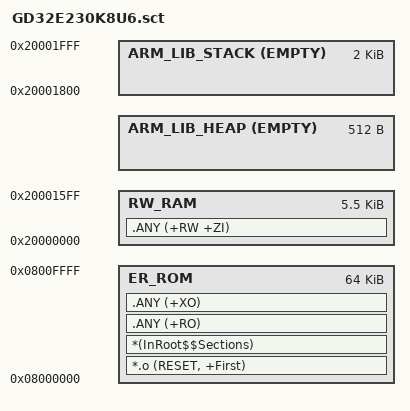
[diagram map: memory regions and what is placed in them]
#! armclang -E --target=arm-arm-none-eabi -mcpu=cortex-m23 -xc
; command above MUST be in first line

/*
;-------- <<< Use Configuration Wizard in Context Menu >>> -------------------
*/

/*--------------------- Flash Configuration ----------------------------------
; <h> Flash Configuration
;   <o0> Flash Base Address <0x0-0xFFFFFFFF:8>
;   <o1> Flash Size (in Bytes) <0x0-0xFFFFFFFF:8>
; </h>
 *----------------------------------------------------------------------------*/
#define __ROM_BASE         0x08000000
#define __ROM_SIZE         0x00010000

/*--------------------- Embedded RAM Configuration ---------------------------
; <h> RAM Configuration
;   <o0> RAM Base Address <0x0-0xFFFFFFFF:8>
;   <o1> RAM Size (in Bytes) <0x0-0xFFFFFFFF:8>
; </h>
 *----------------------------------------------------------------------------*/
#define __RAM_BASE         0x20000000
#define __RAM_SIZE         0x00002000

/*--------------------- Stack / Heap Configuration ---------------------------
; <h> Stack / Heap Configuration
;   <o0> Stack Size (in Bytes) <0x0-0xFFFFFFFF:8>
;   <o1> Heap Size (in Bytes) <0x0-0xFFFFFFFF:8>
; </h>
 *----------------------------------------------------------------------------*/
#define __STACK_SIZE       0x00000800
#define __HEAP_SIZE        0x00000200

#define __STACK_TOP        (__RAM_BASE + __RAM_SIZE)
#define __HEAP_BASE        (AlignExpr(+0, 8))
#define __RW_SIZE          (__RAM_SIZE - __STACK_SIZE - __HEAP_SIZE)

LR_ROM __ROM_BASE __ROM_SIZE {
  ER_ROM __ROM_BASE __ROM_SIZE {
    *.o (RESET, +First)
    *(InRoot$$Sections)
    .ANY (+RO)
    .ANY (+XO)
  }

  RW_RAM __RAM_BASE __RW_SIZE {
    .ANY (+RW +ZI)
  }

#if __HEAP_SIZE > 0
  ARM_LIB_HEAP __HEAP_BASE EMPTY __HEAP_SIZE {
  }
#endif

  ARM_LIB_STACK __STACK_TOP EMPTY -__STACK_SIZE {
  }
}
